# MEC1701Q register map
Vendor: Microchip Technology; Series: MEC1701; File version: 0
CPU: CM4 r1p0, little endian, MPU, FPU, 3 interrupt priority bits, 155 interrupts
Registers are 32-bit, read-write, reset 0x0 unless marked. A register's access mark holds for its fields unless they carry their own. Offsets are from the block's base; [hi:lo] are bit positions; {n}, {i} and the like mark numbered series; 'fields as' and 'values as' point back to an identical list.

## RTC — This is the set of registers that are automatically counted by hardware every 1 second while the block is enabled to run and to update. These registers are: Seconds, Minutes, Hours, Day of Week, Day of Month, Month, and Year.
Base 0x400F5000
0x00 SEC 8-bit — Seconds Register
0x01 SEC_ALARM 8-bit — Seconds Alarm Register
0x02 MIN 8-bit — Minutes Register
0x03 MIN_ALARM 8-bit — Minutes Alarm Register
0x04 HR 8-bit — Hours Register
0x05 HR_ALARM 8-bit — Hours Alarm Register
0x06 DAY_OF_WK 8-bit — Day of Week Register
0x07 DAY_OF_MON 8-bit — Day of Month Register
0x08 MONTH 8-bit
0x09 YEAR 8-bit
0x0A REGA 8-bit — Register A
0x0B REGB 8-bit — Register B
0x0C REGC 8-bit — Register C
0x0D REGD 8-bit — Register D
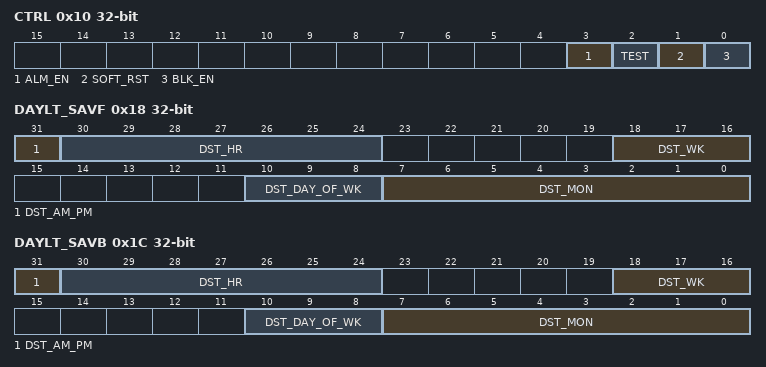
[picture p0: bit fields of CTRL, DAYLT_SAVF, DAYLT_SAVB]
0x10 CTRL — RTC Control Register
  [3] ALM_EN — ALM_EN 1=Enables the Alarm features, 0=Disables the Alarm features
  [2] TEST
  [1] SOFT_RST — SOFT_RST A '1' written to this bit position will trigger the RTC_RST reset, resetting the block and all registers except this one and the Test Register. This bit is self-clearing at the end of the reset, one cycle of Host Bus Clock later, and so requires no waiting.
  [0] BLK_EN — BLK_EN This bit must be '1' in order for the block to function internally. Registers may be initialized first, before setting this bit to '1' to start operation.
0x14 WK_ALARM — Week Alarm Register[7:0] - ALARM_DAY_OF_WEEK This register, if written to a value in the range 1- -7, will inhibit the Alarm interrupt unless this field matches the contents of the Day of Week Register also.
0x18 DAYLT_SAVF — Daylight Savings Forward Register
  [31] DST_AM_PM — This bit selects AM vs. PM, to match bit[7] of the Hours Register if 12-Hour mode is selected in Register B at the time of writing.
  [30:24] DST_HR — This field holds the matching value for bits[6:0] of the Hours register. The written value will be interpreted according to the 24/12 Hour mode and DM mode settings at the time of writing.
  [18:16] DST_WK — 5=Last week of month, 4 =Fourth week of month, 3=Third week of month, 2=Second week of month, 1=First week of month
  [10:8] DST_DAY_OF_WK — This field matches the Day of Week Register bits[2:0].
  [7:0] DST_MON — This field matches the Month Register.
0x1C DAYLT_SAVB — Daylight Savings Backward Register
  fields as DAYLT_SAVF

## PWM0 — This block generates a PWM output that can be used to control 4-wire fans, blinking LEDs, and other similar devices. Each PWM can generate an arbitrary duty cycle output at frequencies from less than 0.1 Hz to 24 MHz. The PWM controller can also used to generate the PROCHOT output and Speaker output.
Base 0x40005800; register names take the prefix PWM_
Same registers: PWM{n} {0x40005800+0x10*n} (n=1..11)
0x00 CNT_ON — This field determines both the frequency and duty cycle of the PWM signal. Setting this field to a value of n will cause the On time of the PWM to be n+1 cycles of the PWM Clock Source. When this field is set to zero and the PWMX_COUNTER_OFF_TIME is not set to zero, the PWM_OUTPUT is held low (Full Off).
0x04 CNT_OFF — This field determine both the frequency and duty cycle of the PWM signal. Setting this field to a value of n will cause the Off time of the PWM to be n+1 cycles of the PWM Clock Source. When this field is set to zero, the PWM_OUTPUT is held high (Full On).
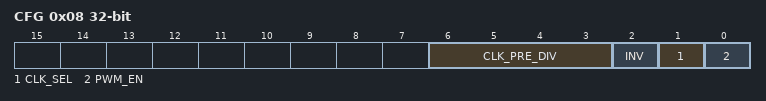
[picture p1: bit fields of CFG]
0x08 CFG — PWMx CFGURATION REGISTER
  [6:3] CLK_PRE_DIV — The Clock source for the 16-bit down counter (see PWMx Counter ON Time Register and PWMx Counter OFF Time Register) is determined by bit D1 of this register. The Clock source is then divided by the value of Pre-Divider+1 and the resulting signal determines the rate at which the down counter will be decremented. For example, a Pre-Divider value of 1 divides the input clock by 2 and a value of 2 divides the input clock by 3. A Pre-Divider of 0 will disable the Pre-Divider option.
  [2] INV — 1= PWM_OUTPUT ON State is active low; 0=PWM_OUTPUT ON State is active high.
  [1] CLK_SEL — This bit determines the clock source used by the PWM duty cycle and frequency control logic. 1=CLOCK_LOW. 0=CLOCK_HIGH
  [0] PWM_EN — When the PWM_EN is set to 0 the internal counters are reset and the internal state machine is set to the OFF state. In addition, the PWM_OUTPUT signal is set to the inactive state as determined by the Invert bit. The PWMx Counter ON Time Register and PWMx Counter OFF Time Register are not affected by the PWM_ENABLE bit and may be read and written while the PWM enable bit is 0. 1=Enabled (default); 0=Disabled (gates clocks to save power).

## Notices in the file
Copyright (c) 2023 Microchip Technology Inc.
SPDX-License-Identifier: Apache-2.0
Licensed under the Apache License, Version 2.0 (the "License");
you may not use this file except in compliance with the License.
You may obtain a copy of the License at
http://www.apache.org/licenses/LICENSE-2.0
Unless required by applicable law or agreed to in writing, software
distributed under the License is distributed on an "AS IS" BASIS,
WITHOUT WARRANTIES OR CONDITIONS OF ANY KIND, either express or implied.
See the License for the specific language governing permissions and
limitations under the License.
